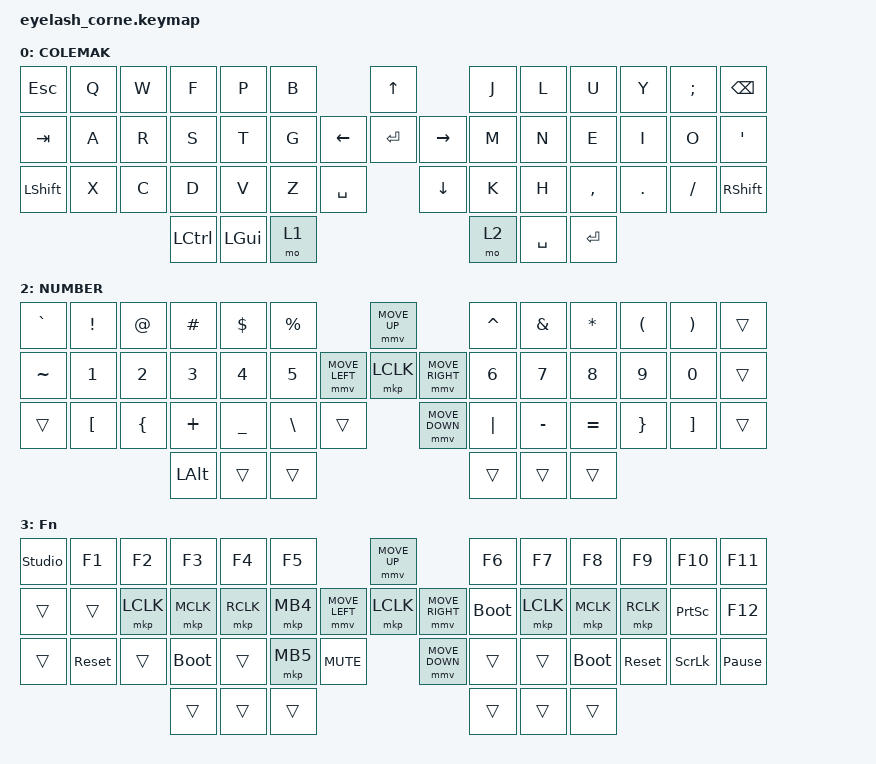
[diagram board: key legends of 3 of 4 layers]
#define ZMK_POINTING_DEFAULT_MOVE_VAL 1200  // 600
#define ZMK_POINTING_DEFAULT_SCRL_VAL 25   // 10

#include <input/processors.dtsi>
#include <zephyr/dt-bindings/input/input-event-codes.h>
#include <behaviors.dtsi>
#include <behaviors/runtime-sensor-rotate.dtsi>
#include <dt-bindings/zmk/bt.h>
#include <dt-bindings/zmk/keys.h>
#include <dt-bindings/zmk/outputs.h>
#include <dt-bindings/zmk/pointing.h>
#include <dt-bindings/zmk/rgb.h>

&soft_off { hold-time-ms = <2000>; };

/ {
    behaviors {
        rsr_vol: rsr_vol {
            compatible = "zmk,behavior-runtime-sensor-rotate";
            #sensor-binding-cells = <0>;
            tap-ms = <5>;
            cw-binding = <&kp C_VOL_UP>;
            ccw-binding = <&kp C_VOL_DN>;
        };

        rsr_trans: rsr_trans {
            compatible = "zmk,behavior-runtime-sensor-rotate";
            #sensor-binding-cells = <0>;
            tap-ms = <0>;
        };
    };

    combos {
        compatible = "zmk,combos";

        softoff {
            bindings = <&soft_off>;
            key-positions = <1 15 29>;
        };
    };

    conditional_layers {
        compatible = "zmk,conditional-layers";

        fn {
            if-layers = <1 2>;
            then-layer = <3>;
        };
    };

    keymap {
        compatible = "zmk,keymap";

        default_layer {
            display-name = "COLEMAK";
            bindings = <
&kp ESC    &kp Q  &kp W  &kp F     &kp P  &kp B                            &kp UP                &kp J      &kp L  &kp U      &kp Y    &kp SEMI  &kp BSPC
&kp TAB    &kp A  &kp R  &kp S     &kp T  &kp G                  &kp LEFT  &kp ENTER  &kp RIGHT  &kp M      &kp N  &kp E      &kp I    &kp O     &kp SQT
&kp LSHFT  &kp X  &kp C  &kp D     &kp V  &kp Z      &kp SPACE             &kp DOWN              &kp K      &kp H  &kp COMMA  &kp DOT  &kp FSLH  &kp RSHFT
                         &kp LCTRL &kp LGUI &mo 1                                                &mo 2      &kp SPACE  &kp ENTER
            >;

            sensor-bindings = <&rsr_vol &rsr_trans>;
        };

        nav_layer {
            display-name = "NAV";
            bindings = <
&trans    &trans   &trans   &trans   &trans   &trans                       &trans                  &trans  &trans  &trans  &trans  &trans  &trans
&trans    &kp LEFT &kp DOWN &kp UP   &kp RIGHT &trans           &trans     &trans      &trans      &trans  &kp H   &kp J   &kp K   &kp L   &trans
&kp LALT  &trans   &trans   &trans   &trans   &trans   &trans              &trans                  &trans  &trans  &trans  &trans  &trans  &kp LALT
	    >;

            sensor-bindings = <&rsr_vol &rsr_trans>;
        };

        num_layer {
            display-name = "NUMBER";
            bindings = <
&kp GRAVE  &kp EXCL   &kp AT    &kp HASH   &kp DLLR   &kp PRCNT                            &mmv MOVE_UP                     &kp CARET  &kp AMPS   &kp ASTRK  &kp LPAR  &kp RPAR  &trans
&kp TILDE  &kp N1     &kp N2    &kp N3     &kp N4     &kp N5               &mmv MOVE_LEFT  &mkp LCLK       &mmv MOVE_RIGHT  &kp N6     &kp N7     &kp N8     &kp N9    &kp N0    &trans
&trans  &kp LBKT   &kp LBRC  &kp PLUS   &kp UNDER  &kp BSLH   &trans                    &mmv MOVE_DOWN                   &kp PIPE   &kp MINUS  &kp EQUAL  &kp RBRC  &kp RBKT  &trans
                             &kp LALT   &trans     &trans                                                                &trans     &trans     &trans
            >;

            sensor-bindings = <&rsr_vol &rsr_trans>;
        };

        layer_3 {
            display-name = "Fn";
            bindings = <
&studio_unlock  &kp F1      &kp F2     &kp F3       &kp F4     &kp F5                                  &mmv MOVE_UP                     &kp F6       &kp F7     &kp F8       &kp F9      &kp F10          &kp F11
&trans          &trans      &mkp LCLK  &mkp MCLK    &mkp RCLK  &mkp MB4                &mmv MOVE_LEFT  &mkp LCLK       &mmv MOVE_RIGHT  &bootloader  &mkp LCLK  &mkp MCLK    &mkp RCLK   &kp PRINTSCREEN  &kp F12
&trans          &sys_reset  &trans     &bootloader  &trans     &mkp MB5  &kp C_MUTE                    &mmv MOVE_DOWN                   &trans       &trans     &bootloader  &sys_reset  &kp SCROLLLOCK   &kp PAUSE_BREAK
                                       &trans       &trans     &trans                                                                   &trans       &trans     &trans
            >;

            sensor-bindings = <&rsr_vol &rsr_trans>;
        };
    };
};
